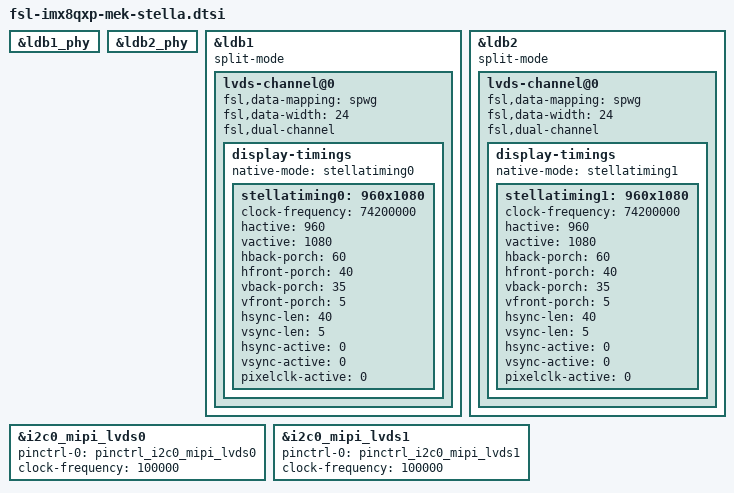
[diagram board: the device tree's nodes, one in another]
&ldb1_phy {
    status = "okay";
};

&ldb2_phy {
    status = "okay";
};

&ldb1 {
    status = "okay";
    split-mode;
    lvds-channel@0 {
        fsl,data-mapping = "spwg";
        fsl,data-width = <24>;
        fsl,dual-channel;
        status = "okay";
        display-timings {
            native-mode = <&stellatiming0>;
            stellatiming0: 960x1080 {
                clock-frequency = <74200000>;
                hactive = <960>;
                vactive = <1080>;
                hback-porch = <60>;
                hfront-porch = <40>;
                vback-porch = <35>;
                vfront-porch = <5>;
                hsync-len = <40>;
                vsync-len = <5>;
                hsync-active = <0>;
                vsync-active = <0>;
                pixelclk-active = <0>;
                
            };
        };
    };
};

&ldb2 {
    status = "okay";
    split-mode;
    lvds-channel@0 {
        fsl,data-mapping = "spwg";
        fsl,data-width = <24>;
        fsl,dual-channel;
        status = "okay";
        display-timings {
            native-mode = <&stellatiming1>;
            stellatiming1: 960x1080 {
                clock-frequency = <74200000>;
                hactive = <960>;
                vactive = <1080>;
                hback-porch = <60>;
                hfront-porch = <40>;
                vback-porch = <35>;
                vfront-porch = <5>;
                hsync-len = <40>;
                vsync-len = <5>;
                hsync-active = <0>;
                vsync-active = <0>;
                pixelclk-active = <0>;
                
            };
        };
    };
};


&i2c0_mipi_lvds0 {
    #address-cells = <1>;
    #size-cells = <0>;
    pinctrl-names = "default";
    pinctrl-0 = <&pinctrl_i2c0_mipi_lvds0>;
    clock-frequency = <100000>;
    status = "okay";
};

&i2c0_mipi_lvds1 {
    #address-cells = <1>;
    #size-cells = <0>;
    pinctrl-names = "default";
    pinctrl-0 = <&pinctrl_i2c0_mipi_lvds1>;
    clock-frequency = <100000>;
    status = "okay";
};



